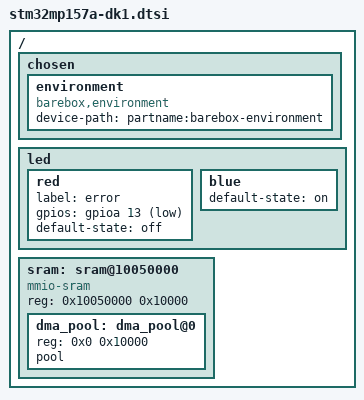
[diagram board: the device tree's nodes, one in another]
// SPDX-License-Identifier: (GPL-2.0+ OR BSD-3-Clause)
/*
 * Copyright (C) STMicroelectronics 2018 - All Rights Reserved
 * Author: Alexandre Torgue <alexandre.torgue@st.com>.
 */

#include "stm32mp157c.dtsi"
#include <dt-bindings/gpio/gpio.h>

/ {
	chosen {
		environment {
			compatible = "barebox,environment";
			device-path = &sdmmc1, "partname:barebox-environment";
		};
	};

	led {
		red {
			label = "error";
			gpios = <&gpioa 13 GPIO_ACTIVE_LOW>;
			default-state = "off";
			status = "okay";
		};

		blue {
			default-state = "on";
		};
	};

	sram: sram@10050000 {
		compatible = "mmio-sram";
		reg = <0x10050000 0x10000>;
		#address-cells = <1>;
		#size-cells = <1>;
		ranges = <0 0x10050000 0x10000>;

		dma_pool: dma_pool@0 {
			reg = <0x0 0x10000>;
			pool;
		};
	};
};
